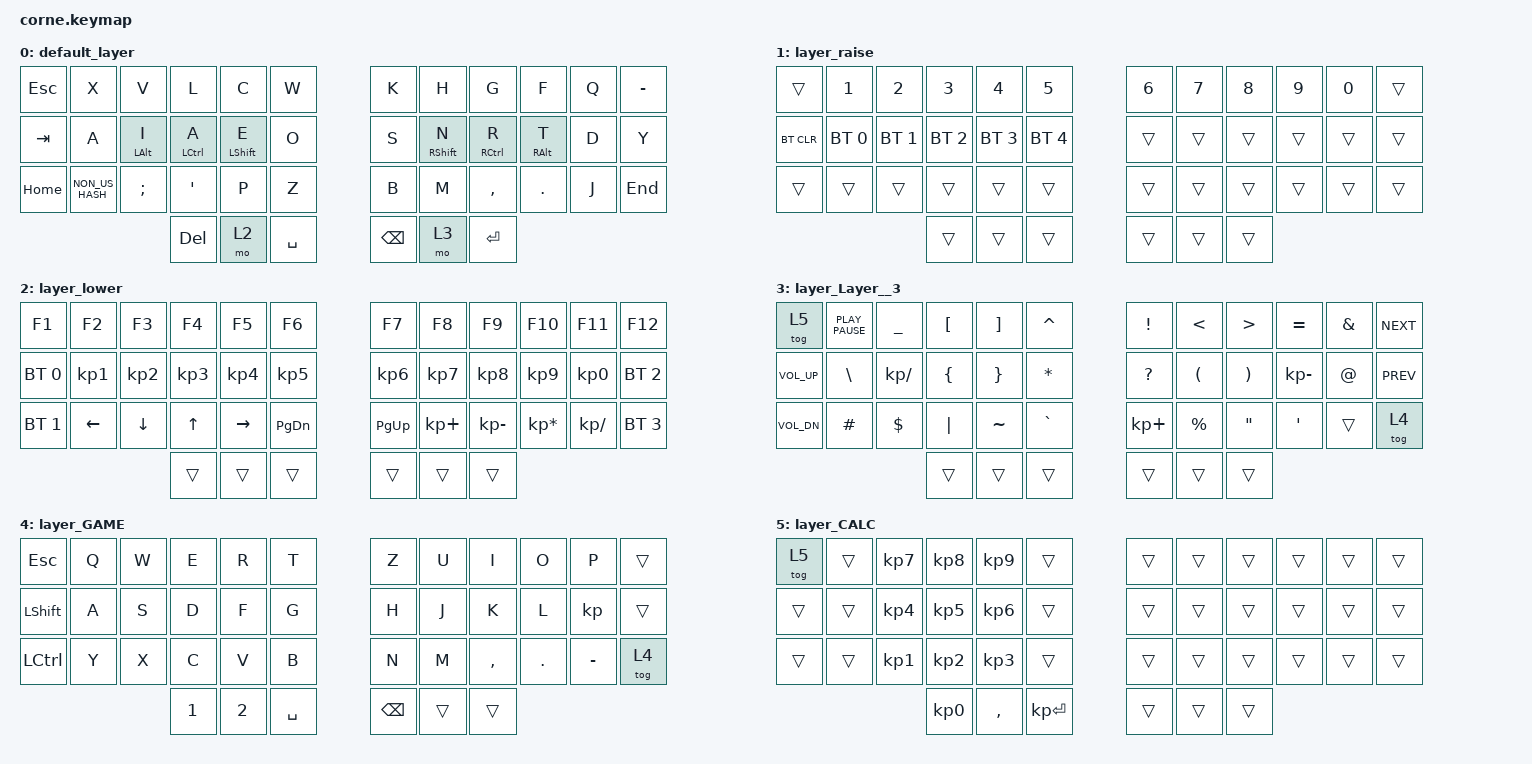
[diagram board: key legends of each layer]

/*
 * Copyright (c) 2020 The ZMK Contributors
 *
 * SPDX-License-Identifier: MIT
 */


/* THIS FILE WAS GENERATED!
 *
 * This file was generated automatically. You may or may not want to
 * edit it directly.
 */

#include <behaviors.dtsi>
#include <dt-bindings/zmk/keys.h>
#include <dt-bindings/zmk/bt.h>

/ {
    keymap {
        compatible = "zmk,keymap";


        default_layer {
            bindings = <
  &kp ESC            &kp X           &kp V               &kp L             &kp C      &kp W                    &kp K              &kp H                &kp G            &kp F   &kp Q  &kp MINUS
  &kp TAB            &kp A  &mt LEFT_ALT I  &mt LEFT_CONTROL A  &mt LEFT_SHIFT E      &kp O                    &kp S  &mt RIGHT_SHIFT N  &mt RIGHT_CONTROL R  &mt RIGHT_ALT T   &kp D      &kp Y
 &kp HOME  &kp NON_US_HASH   &kp SEMICOLON    &kp SINGLE_QUOTE             &kp P      &kp Z                    &kp B              &kp M            &kp COMMA          &kp DOT   &kp J    &kp END
                                                    &kp DELETE             &mo 2  &kp SPACE            &kp BACKSPACE              &mo 3            &kp ENTER
            >;
        };

        layer_raise {
            bindings = <
     &trans        &kp N1        &kp N2        &kp N3        &kp N4        &kp N5            &kp N6  &kp N7  &kp N8  &kp N9  &kp N0  &trans
 &bt BT_CLR  &bt BT_SEL 0  &bt BT_SEL 1  &bt BT_SEL 2  &bt BT_SEL 3  &bt BT_SEL 4            &trans  &trans  &trans  &trans  &trans  &trans
     &trans        &trans        &trans        &trans        &trans        &trans            &trans  &trans  &trans  &trans  &trans  &trans
                                               &trans        &trans        &trans            &trans  &trans  &trans
            >;
        };

        layer_lower {
            bindings = <
       &kp F1           &kp F2           &kp F3           &kp F4           &kp F5           &kp F6                     &kp F7           &kp F8           &kp F9          &kp F10          &kp F11       &kp F12
 &bt BT_SEL 0  &kp KP_NUMBER_1  &kp KP_NUMBER_2  &kp KP_NUMBER_3  &kp KP_NUMBER_4  &kp KP_NUMBER_5            &kp KP_NUMBER_6  &kp KP_NUMBER_7  &kp KP_NUMBER_8  &kp KP_NUMBER_9  &kp KP_NUMBER_0  &bt BT_SEL 2
 &bt BT_SEL 1         &kp LEFT         &kp DOWN           &kp UP        &kp RIGHT        &kp PG_DN                  &kp PG_UP      &kp KP_PLUS     &kp KP_MINUS  &kp KP_MULTIPLY    &kp KP_DIVIDE  &bt BT_SEL 3
                                                          &trans           &trans           &trans                     &trans           &trans           &trans
            >;
        };

        layer_Layer__3 {
            bindings = <
       &tog 5  &kp K_PLAY_PAUSE  &kp UNDERSCORE  &kp LEFT_BRACKET  &kp RIGHT_BRACKET     &kp CARET            &kp EXCLAMATION  &kp LESS_THAN  &kp GREATER_THAN         &kp EQUAL  &kp AMPERSAND  &kp K_NEXT
 &kp K_VOL_UP     &kp BACKSLASH    &kp KP_SLASH    &kp LEFT_BRACE    &kp RIGHT_BRACE  &kp ASTERISK               &kp QUESTION       &kp LPAR          &kp RPAR      &kp KP_MINUS         &kp AT  &kp K_PREV
 &kp K_VOL_DN          &kp HASH      &kp DOLLAR          &kp PIPE          &kp TILDE     &kp GRAVE                &kp KP_PLUS    &kp PERCENT           &kp DQT  &kp SINGLE_QUOTE         &trans      &tog 4
                                                           &trans             &trans        &trans                     &trans         &trans            &trans
            >;
        };

        layer_GAME {
            bindings = <
        &kp ESC   &kp Q   &kp W   &kp E   &kp R      &kp T                    &kp Z   &kp U      &kp I    &kp O      &kp P  &trans
 &kp LEFT_SHIFT   &kp A   &kp S   &kp D   &kp F      &kp G                    &kp H   &kp J      &kp K    &kp L        &kp  &trans
      &kp LCTRL   &kp Y   &kp X   &kp C   &kp V      &kp B                    &kp N   &kp M  &kp COMMA  &kp DOT  &kp MINUS  &tog 4
                                 &kp N1  &kp N2  &kp SPACE            &kp BACKSPACE  &trans     &trans
            >;
        };

        layer_CALC {
            bindings = <
 &tog 5  &trans  &kp KP_N7        &kp KP_N8  &kp KP_NUMBER_9        &trans            &trans  &trans  &trans  &trans  &trans  &trans
 &trans  &trans  &kp KP_N4        &kp KP_N5        &kp KP_N6        &trans            &trans  &trans  &trans  &trans  &trans  &trans
 &trans  &trans  &kp KP_N1  &kp KP_NUMBER_2        &kp KP_N3        &trans            &trans  &trans  &trans  &trans  &trans  &trans
                            &kp KP_NUMBER_0        &kp COMMA  &kp KP_ENTER            &trans  &trans  &trans
            >;
        };

    };
};
